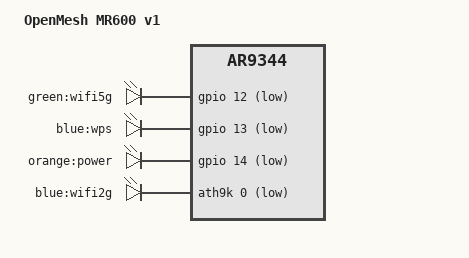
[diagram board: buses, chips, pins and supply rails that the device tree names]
// SPDX-License-Identifier: GPL-2.0-or-later OR MIT

#include "ar9344_openmesh_mr600.dtsi"

/ {
	compatible = "openmesh,mr600-v1", "qca,ar9344";
	model = "OpenMesh MR600 v1";

	aliases {
		led-boot = &led_power_orange;
		led-failsafe = &led_power_orange;
		led-running = &led_power_orange;
		led-upgrade = &led_power_orange;
	};

	leds {
		compatible = "gpio-leds";

		wifi5g_green {
			label = "green:wifi5g";
			gpios = <&gpio 12 GPIO_ACTIVE_LOW>;
			linux,default-trigger = "phy0tpt";
		};

		wps_blue {
			label = "blue:wps";
			gpios = <&gpio 13 GPIO_ACTIVE_LOW>;
		};

		led_power_orange: power_orange {
			label = "orange:power";
			gpios = <&gpio 14 GPIO_ACTIVE_LOW>;
			default-state = "on";
		};
	};

	leds-ath9k {
		compatible = "gpio-leds";

		wifi2g {
			label = "blue:wifi2g";
			gpios = <&ath9k 0 GPIO_ACTIVE_LOW>;
			linux,default-trigger = "phy1tpt";
		};
	};
};
